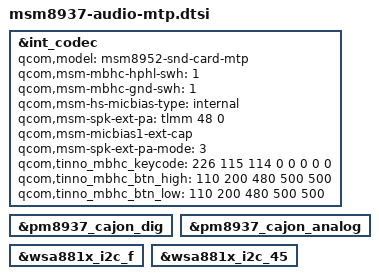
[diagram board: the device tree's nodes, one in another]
/*
 * Copyright (c) 2015-2016, The Linux Foundation. All rights reserved.
 *
 * This program is free software; you can redistribute it and/or modify
 * it under the terms of the GNU General Public License version 2 and
 * only version 2 as published by the Free Software Foundation.
 *
 * This program is distributed in the hope that it will be useful,
 * but WITHOUT ANY WARRANTY; without even the implied warranty of
 * MERCHANTABILITY or FITNESS FOR A PARTICULAR PURPOSE.  See the
 * GNU General Public License for more details.
 */

&int_codec {
	status = "okay";
	qcom,model = "msm8952-snd-card-mtp";
	//luzhihua modify start
	qcom,msm-mbhc-hphl-swh = <1>;
	qcom,msm-mbhc-gnd-swh = <1>;
	qcom,msm-hs-micbias-type = "internal";
	qcom,msm-spk-ext-pa = <&tlmm 48 0>;
	qcom,msm-micbias1-ext-cap;

    qcom,msm-spk-ext-pa-mode = <3>;
    qcom,tinno_mbhc_keycode = <226 115 114 0 0 0 0 0>;
    qcom,tinno_mbhc_btn_high = <110 200 480 500 500>;
    qcom,tinno_mbhc_btn_low = <110 200 480 500 500>;
	//luzhihua modify end

};

&pm8937_cajon_dig {
	status = "okay";
};

&pm8937_cajon_analog {
	status = "okay";
};

&wsa881x_i2c_f {
	status = "okay";
};

&wsa881x_i2c_45 {
	status = "okay";
};
